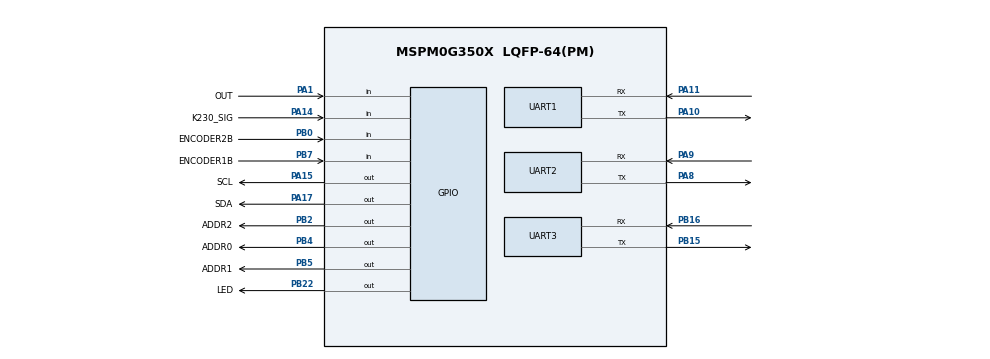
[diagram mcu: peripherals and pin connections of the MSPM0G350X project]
/**
 * @cliArgs --device "MSPM0G350X" --part "Default" --package "LQFP-64(PM)" --product "mspm0_sdk@2.10.00.04"
 * @versions {"tool":"1.26.2+4477"}
 */

/**
 * Import the modules used in this configuration.
 */
const CAPTURE  = scripting.addModule("/ti/driverlib/CAPTURE", {}, false);
const CAPTURE1 = CAPTURE.addInstance();
const GPIO     = scripting.addModule("/ti/driverlib/GPIO", {}, false);
const GPIO1    = GPIO.addInstance();
const GPIO2    = GPIO.addInstance();
const GPIO3    = GPIO.addInstance();
const GPIO4    = GPIO.addInstance();
const GPIO5    = GPIO.addInstance();
const GPIO6    = GPIO.addInstance();
const GPIO7    = GPIO.addInstance();
const I2C      = scripting.addModule("/ti/driverlib/I2C", {}, false);
const I2C1     = I2C.addInstance();
const SYSCTL   = scripting.addModule("/ti/driverlib/SYSCTL");
const SYSTICK  = scripting.addModule("/ti/driverlib/SYSTICK");
const TIMER    = scripting.addModule("/ti/driverlib/TIMER", {}, false);
const TIMER1   = TIMER.addInstance();
const UART     = scripting.addModule("/ti/driverlib/UART", {}, false);
const UART1    = UART.addInstance();
const UART2    = UART.addInstance();
const UART3    = UART.addInstance();
const UART4    = UART.addInstance();

/**
 * Write custom configuration values to the imported modules.
 */
CAPTURE1.$name                              = "ENCODER_A1";
CAPTURE1.timerPeriod                        = "1 ms";
CAPTURE1.interrupts                         = ["CC0_DN"];
CAPTURE1.timerStartTimer                    = true;
CAPTURE1.ccp0PinConfig.hideOutputInversion  = scripting.forceWrite(false);
CAPTURE1.ccp0PinConfig.onlyInternalResistor = scripting.forceWrite(false);
CAPTURE1.ccp0PinConfig.passedPeripheralType = scripting.forceWrite("Digital");
CAPTURE1.ccp0PinConfig.$name                = "ti_driverlib_gpio_GPIOPinGeneric3";

const Board = scripting.addModule("/ti/driverlib/Board", {}, false);

GPIO1.$name                          = "GPIO_ENCODER";
GPIO1.associatedPins.create(2);
GPIO1.associatedPins[0].$name        = "ENCODER1B";
GPIO1.associatedPins[0].direction    = "INPUT";
GPIO1.associatedPins[0].assignedPort = "PORTB";
GPIO1.associatedPins[0].assignedPin  = "7";
GPIO1.associatedPins[0].pin.$assign  = "PB7";
GPIO1.associatedPins[1].$name        = "ENCODER2B";
GPIO1.associatedPins[1].direction    = "INPUT";
GPIO1.associatedPins[1].assignedPort = "PORTB";
GPIO1.associatedPins[1].assignedPin  = "0";
GPIO1.associatedPins[1].pin.$assign  = "PB0";

GPIO2.$name                          = "GPIO_GREY_ADDR";
GPIO2.associatedPins.create(3);
GPIO2.associatedPins[0].$name        = "ADDR0";
GPIO2.associatedPins[0].assignedPort = "PORTB";
GPIO2.associatedPins[0].assignedPin  = "4";
GPIO2.associatedPins[0].pin.$assign  = "PB4";
GPIO2.associatedPins[1].$name        = "ADDR1";
GPIO2.associatedPins[1].assignedPort = "PORTB";
GPIO2.associatedPins[1].assignedPin  = "5";
GPIO2.associatedPins[1].pin.$assign  = "PB5";
GPIO2.associatedPins[2].$name        = "ADDR2";
GPIO2.associatedPins[2].assignedPort = "PORTB";
GPIO2.associatedPins[2].assignedPin  = "2";
GPIO2.associatedPins[2].pin.$assign  = "PB2";

GPIO3.$name                         = "GPIO_LED";
GPIO3.associatedPins[0].$name       = "LED";
GPIO3.associatedPins[0].pin.$assign = "PB22";

GPIO4.$name                          = "GPIO_GREY_OUT";
GPIO4.associatedPins[0].$name        = "OUT";
GPIO4.associatedPins[0].direction    = "INPUT";
GPIO4.associatedPins[0].assignedPort = "PORTA";
GPIO4.associatedPins[0].assignedPin  = "1";
GPIO4.associatedPins[0].pin.$assign  = "PA1";

GPIO5.$name                              = "I2C";
GPIO5.associatedPins.create(2);
GPIO5.associatedPins[0].$name            = "SDA";
GPIO5.associatedPins[0].assignedPort     = "PORTA";
GPIO5.associatedPins[0].assignedPin      = "17";
GPIO5.associatedPins[0].initialValue     = "SET";
GPIO5.associatedPins[0].internalResistor = "PULL_UP";
GPIO5.associatedPins[0].pin.$assign      = "PA17";
GPIO5.associatedPins[1].$name            = "SCL";
GPIO5.associatedPins[1].assignedPort     = "PORTA";
GPIO5.associatedPins[1].assignedPin      = "15";
GPIO5.associatedPins[1].initialValue     = "SET";
GPIO5.associatedPins[1].internalResistor = "PULL_UP";
GPIO5.associatedPins[1].pin.$assign      = "PA15";

GPIO6.$name                              = "GPIO_BUTTON";
GPIO6.associatedPins.create(4);
GPIO6.associatedPins[0].direction        = "INPUT";
GPIO6.associatedPins[0].internalResistor = "PULL_UP";
GPIO6.associatedPins[0].assignedPort     = "PORTA";
GPIO6.associatedPins[0].assignedPin      = "7";
GPIO6.associatedPins[0].interruptEn      = true;
GPIO6.associatedPins[0].polarity         = "FALL";
GPIO6.associatedPins[0].inputFilter      = "8_CYCLES";
GPIO6.associatedPins[0].$name            = "BTN_3";
GPIO6.associatedPins[1].direction        = "INPUT";
GPIO6.associatedPins[1].internalResistor = "PULL_UP";
GPIO6.associatedPins[1].assignedPort     = "PORTA";
GPIO6.associatedPins[1].assignedPin      = "18";
GPIO6.associatedPins[1].interruptEn      = true;
GPIO6.associatedPins[1].polarity         = "FALL";
GPIO6.associatedPins[1].inputFilter      = "8_CYCLES";
GPIO6.associatedPins[1].$name            = "BTN_1";
GPIO6.associatedPins[2].direction        = "INPUT";
GPIO6.associatedPins[2].internalResistor = "PULL_UP";
GPIO6.associatedPins[2].assignedPort     = "PORTB";
GPIO6.associatedPins[2].assignedPin      = "1";
GPIO6.associatedPins[2].interruptEn      = true;
GPIO6.associatedPins[2].polarity         = "FALL";
GPIO6.associatedPins[2].inputFilter      = "8_CYCLES";
GPIO6.associatedPins[2].$name            = "BTN_4";
GPIO6.associatedPins[3].direction        = "INPUT";
GPIO6.associatedPins[3].internalResistor = "PULL_UP";
GPIO6.associatedPins[3].assignedPort     = "PORTB";
GPIO6.associatedPins[3].assignedPin      = "14";
GPIO6.associatedPins[3].interruptEn      = true;
GPIO6.associatedPins[3].polarity         = "FALL";
GPIO6.associatedPins[3].inputFilter      = "8_CYCLES";
GPIO6.associatedPins[3].$name            = "BTN_2";

GPIO7.$name                              = "GPIO_K230";
GPIO7.associatedPins[0].$name            = "K230_SIG";
GPIO7.associatedPins[0].direction        = "INPUT";
GPIO7.associatedPins[0].internalResistor = "PULL_DOWN";
GPIO7.associatedPins[0].assignedPort     = "PORTA";
GPIO7.associatedPins[0].assignedPin      = "14";
GPIO7.associatedPins[0].pin.$assign      = "PA14";

I2C1.$name                             = "I2C_Motor";
I2C1.basicEnableController             = true;
I2C1.basicControllerStandardBusSpeed   = "Fast";
I2C1.sdaPinConfig.hideOutputInversion  = scripting.forceWrite(false);
I2C1.sdaPinConfig.onlyInternalResistor = scripting.forceWrite(false);
I2C1.sdaPinConfig.passedPeripheralType = scripting.forceWrite("Digital");
I2C1.sdaPinConfig.$name                = "ti_driverlib_gpio_GPIOPinGeneric4";
I2C1.sclPinConfig.hideOutputInversion  = scripting.forceWrite(false);
I2C1.sclPinConfig.onlyInternalResistor = scripting.forceWrite(false);
I2C1.sclPinConfig.passedPeripheralType = scripting.forceWrite("Digital");
I2C1.sclPinConfig.$name                = "ti_driverlib_gpio_GPIOPinGeneric10";

SYSCTL.clockTreeEn = true;

SYSTICK.periodEnable    = true;
SYSTICK.period          = 32000;
SYSTICK.interruptEnable = true;
SYSTICK.systickEnable   = true;

TIMER1.timerClkPrescale = 5;
TIMER1.timerMode        = "PERIODIC";
TIMER1.timerPeriod      = "10 ms";
TIMER1.timerStartTimer  = true;
TIMER1.interrupts       = ["ZERO"];
TIMER1.$name            = "CLOCK";

UART1.enableFIFO                       = true;
UART1.txFifoThreshold                  = "DL_UART_TX_FIFO_LEVEL_1_4_EMPTY";
UART1.enabledInterrupts                = ["RX"];
UART1.$name                            = "UART_IMU";
UART1.targetBaudRate                   = 115200;
UART1.peripheral.rxPin.$assign         = "PA11";
UART1.peripheral.txPin.$assign         = "PA10";
UART1.txPinConfig.direction            = scripting.forceWrite("OUTPUT");
UART1.txPinConfig.hideOutputInversion  = scripting.forceWrite(false);
UART1.txPinConfig.onlyInternalResistor = scripting.forceWrite(false);
UART1.txPinConfig.passedPeripheralType = scripting.forceWrite("Digital");
UART1.txPinConfig.$name                = "ti_driverlib_gpio_GPIOPinGeneric1";
UART1.txPinConfig.enableConfig         = true;
UART1.rxPinConfig.hideOutputInversion  = scripting.forceWrite(false);
UART1.rxPinConfig.onlyInternalResistor = scripting.forceWrite(false);
UART1.rxPinConfig.passedPeripheralType = scripting.forceWrite("Digital");
UART1.rxPinConfig.$name                = "ti_driverlib_gpio_GPIOPinGeneric5";

UART2.targetBaudRate                   = 115200;
UART2.enableFIFO                       = true;
UART2.$name                            = "UART_K230";
UART2.enabledInterrupts                = ["RX"];
UART2.peripheral.rxPin.$assign         = "PA9";
UART2.peripheral.txPin.$assign         = "PA8";
UART2.txPinConfig.direction            = scripting.forceWrite("OUTPUT");
UART2.txPinConfig.hideOutputInversion  = scripting.forceWrite(false);
UART2.txPinConfig.onlyInternalResistor = scripting.forceWrite(false);
UART2.txPinConfig.passedPeripheralType = scripting.forceWrite("Digital");
UART2.txPinConfig.$name                = "ti_driverlib_gpio_GPIOPinGeneric6";
UART2.txPinConfig.enableConfig         = true;
UART2.rxPinConfig.hideOutputInversion  = scripting.forceWrite(false);
UART2.rxPinConfig.onlyInternalResistor = scripting.forceWrite(false);
UART2.rxPinConfig.passedPeripheralType = scripting.forceWrite("Digital");
UART2.rxPinConfig.$name                = "ti_driverlib_gpio_GPIOPinGeneric7";
UART2.rxPinConfig.enableConfig         = true;

UART3.enableFIFO                       = true;
UART3.txFifoThreshold                  = "DL_UART_TX_FIFO_LEVEL_1_4_EMPTY";
UART3.$name                            = "UART_Motor";
UART3.targetBaudRate                   = 115200;
UART3.enabledDMATXTriggers             = "DL_UART_DMA_INTERRUPT_TX";
UART3.peripheral.rxPin.$assign         = "PB16";
UART3.peripheral.txPin.$assign         = "PB15";
UART3.txPinConfig.direction            = scripting.forceWrite("OUTPUT");
UART3.txPinConfig.hideOutputInversion  = scripting.forceWrite(false);
UART3.txPinConfig.onlyInternalResistor = scripting.forceWrite(false);
UART3.txPinConfig.passedPeripheralType = scripting.forceWrite("Digital");
UART3.txPinConfig.$name                = "ti_driverlib_gpio_GPIOPinGeneric8";
UART3.txPinConfig.enableConfig         = true;
UART3.rxPinConfig.hideOutputInversion  = scripting.forceWrite(false);
UART3.rxPinConfig.onlyInternalResistor = scripting.forceWrite(false);
UART3.rxPinConfig.passedPeripheralType = scripting.forceWrite("Digital");
UART3.rxPinConfig.internalResistor     = "PULL_UP";
UART3.rxPinConfig.$name                = "ti_driverlib_gpio_GPIOPinGeneric9";
UART3.rxPinConfig.enableConfig         = true;
UART3.DMA_CHANNEL_TX.$name             = "DMA_CH0";
UART3.DMA_CHANNEL_TX.addressMode       = "b2f";
UART3.DMA_CHANNEL_TX.srcLength         = "BYTE";
UART3.DMA_CHANNEL_TX.dstLength         = "BYTE";

UART4.$name                            = "UART_VOFA";
UART4.targetBaudRate                   = 115200;
UART4.enabledInterrupts                = ["RX"];
UART4.enabledDMATXTriggers             = "DL_UART_DMA_INTERRUPT_TX";
UART4.txPinConfig.direction            = scripting.forceWrite("OUTPUT");
UART4.txPinConfig.hideOutputInversion  = scripting.forceWrite(false);
UART4.txPinConfig.onlyInternalResistor = scripting.forceWrite(false);
UART4.txPinConfig.passedPeripheralType = scripting.forceWrite("Digital");
UART4.txPinConfig.$name                = "ti_driverlib_gpio_GPIOPinGeneric0";
UART4.rxPinConfig.hideOutputInversion  = scripting.forceWrite(false);
UART4.rxPinConfig.onlyInternalResistor = scripting.forceWrite(false);
UART4.rxPinConfig.passedPeripheralType = scripting.forceWrite("Digital");
UART4.rxPinConfig.$name                = "ti_driverlib_gpio_GPIOPinGeneric2";
UART4.DMA_CHANNEL_TX.$name             = "DMA_CH1";
UART4.DMA_CHANNEL_TX.srcLength         = "BYTE";
UART4.DMA_CHANNEL_TX.dstLength         = "BYTE";
UART4.DMA_CHANNEL_TX.addressMode       = "b2f";
UART4.DMA_CHANNEL_TX.enableInterrupt   = true;

/**
 * Pinmux solution for unlocked pins/peripherals. This ensures that minor changes to the automatic solver in a future
 * version of the tool will not impact the pinmux you originally saw.  These lines can be completely deleted in order to
 * re-solve from scratch.
 */
CAPTURE1.peripheral.$suggestSolution             = "TIMA1";
CAPTURE1.peripheral.ccp0Pin.$suggestSolution     = "PA28";
Board.peripheral.$suggestSolution                = "DEBUGSS";
Board.peripheral.swclkPin.$suggestSolution       = "PA20";
Board.peripheral.swdioPin.$suggestSolution       = "PA19";
GPIO6.associatedPins[0].pin.$suggestSolution     = "PA7";
GPIO6.associatedPins[1].pin.$suggestSolution     = "PA18";
GPIO6.associatedPins[2].pin.$suggestSolution     = "PB1";
GPIO6.associatedPins[3].pin.$suggestSolution     = "PB14";
I2C1.peripheral.$suggestSolution                 = "I2C0";
I2C1.peripheral.sdaPin.$suggestSolution          = "PA0";
I2C1.peripheral.sclPin.$suggestSolution          = "PA31";
TIMER1.peripheral.$suggestSolution               = "TIMA0";
UART1.peripheral.$suggestSolution                = "UART0";
UART2.peripheral.$suggestSolution                = "UART1";
UART3.peripheral.$suggestSolution                = "UART2";
UART3.DMA_CHANNEL_TX.peripheral.$suggestSolution = "DMA_CH1";
UART4.peripheral.$suggestSolution                = "UART3";
UART4.peripheral.rxPin.$suggestSolution          = "PA13";
UART4.peripheral.txPin.$suggestSolution          = "PA26";
UART4.DMA_CHANNEL_TX.peripheral.$suggestSolution = "DMA_CH0";
